# gcr_es17 register map
Registers are access not given, no defined reset value unless marked. A register's access mark holds for its fields unless they carry their own. Offsets are from the block's base; lines under a group give offsets from that group; [hi:lo] are bit positions; {n}, {i} and the like mark numbered series; 'fields as' and 'values as' point back to an identical list; <NAME> marks a mode.

## Memory map
0x40000000 GCR size 0x400 — Global Control Registers.

## GCR — Global Control Registers.
Base 0x40000000
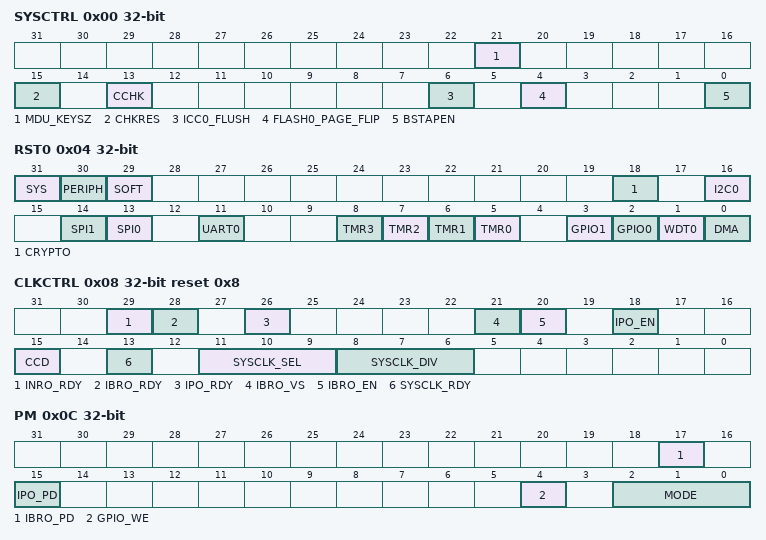
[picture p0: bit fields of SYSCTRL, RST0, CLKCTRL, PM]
0x00 SYSCTRL — System Control.
  [21] MDU_KEYSZ — MDU Key Size. This register defines the size of AES key that is used in the memory protection logic.
    0=128 bit key; 1=256 bit key
  [15] CHKRES — ROM Checksum Result. This bit is only valid when CHKRD=1.
    0=pass (ROM Checksum Correct.); 1=fail (ROM Checksum Fail.)
  [13] CCHK — Compute ROM Checksum. This bit is self-cleared when calculation is completed. Once set, software clearing this bit is ignored and the bit will remain set until the operation is completed.
    0=complete (No operation/complete.); 1=Start operation
  [6] ICC0_FLUSH — Code Cache Flush. This bit is used to flush the code caches and the instruction buffer of the Cortex-M4.
    0=Normal Code Cache Operation; 1=flush (Code Caches and CPU instruction buffer are flushed)
  [4] FLASH0_PAGE_FLIP — Flips the Flash bottom and top halves. (Depending on the total flash size, each half is either 256K or 512K). Initiating a flash page flip will cause a flush of both the data buffer on the DCODE bus and the internal instruction buffer.
    0=normal (Physical layout matches logical layout.); 1=swapped (Bottom half mapped to logical top half and vice versa.)
  [0] BSTAPEN — Boundary Scan TAP enable. When enabled, the JTAG port is connected to the Boundary Scan TAP. Otherwise, the port is connected to the ARM ICE function. This bit is reset by the POR. Reset value and access depend on the part number.
    0=dis (Boundary Scan TAP port disabled.); 1=en (Boundary Scan TAP port enabled.)
0x04 RST0 — Reset.
  [31] SYS — System Reset. Setting this bit to 1 resets the CPU core and all peripherals, including the watchdog timer.
  [30] PERIPH — Peripheral Reset. Setting this bit to 1 resets all peripherals. The CPU core, the watchdog timer, and all GPIO pins are unaffected by this reset.
  [29] SOFT — Soft Reset. Setting this bit to 1 resets everything except the CPU and the watchdog timer.
  [18] CRYPTO — Cryptographic Reset. Setting this bit to 1 resets the AES block, the SHA block and the DES block.
  [16] I2C0 — I2C0 Reset.
  [14] SPI1 — SPI1 Reset. Setting this bit to 1 resets all SPI 1 blocks.
  [13] SPI0 — SPI0 Reset. Setting this bit to 1 resets all SPI 0 blocks.
  [11] UART0 — UART0 Reset. Setting this bit to 1 resets all UART 0 blocks.
  [n+5] TMR{n} (n=0..3) — Timer{n} Reset. Setting this bit to 1 resets Timer {n} blocks.
  [3] GPIO1 — GPIO1 Reset. Setting this bit to 1 resets GPIO1 pins to their default states.
  [2] GPIO0 — GPIO0 Reset. Setting this bit to 1 resets GPIO0 pins to their default states.
  [1] WDT0 — Watchdog Timer Reset.
  [0] DMA — DMA Reset.
0x08 CLKCTRL reset 0x8 — Clock Control.
  [29] INRO_RDY — Internal Nano Ring Oscillator Low Frequency Reference Clock Ready.
  [28] IBRO_RDY — Internal Baud Rate Oscillator Ready.
  [26] IPO_RDY — Internal Primary Oscillator Ready.
  [21] IBRO_VS — 7.3728MHz Internal Oscillator Voltage Source Select
  [20] IBRO_EN — 8MHz High Frequency Internal Reference Clock Enable.
  [18] IPO_EN — 96MHz High Frequency Internal Reference Clock Enable.
  [15] CCD ro — Cryptographic clock divider
    0=non_div (The cryptographic accelerator clock is running in non-divided mode.); 1=div (The cryptographic accelerator clock is running in divided mode.)
  [13] SYSCLK_RDY ro — Clock Ready. This read only bit reflects whether the currently selected system clock source is running.
    0=busy (Switchover to the new clock source (as selected by CLKSEL) has not yet occurred.); 1=ready (System clock running from CLKSEL clock source.)
  [11:9] SYSCLK_SEL — Clock Source Select. This 3 bit field selects the source for the system clock.
    0=IPO (Internal Primary Oscilatior Clock); 3=INRO (8kHz Internal Nano Ring Oscillator is used for the system clock.); 5=IBRO (The internal Baud Rate oscillator is used for the system clock.)
  [8:6] SYSCLK_DIV — Prescaler Select. This 3 bit field sets the system operating frequency by controlling the prescaler that divides the output of the PLL0.
    0=div1 (Divide by 1.); 1=div2 (Divide by 2.); 2=div4 (Divide by 4.); 3=div8 (Divide by 8.); 4=div16 (Divide by 16.); 5=div32 (Divide by 32.); 6=div64 (Divide by 64.); 7=div128 (Divide by 128.)
0x0C PM — Power Management.
  [17] IBRO_PD — Internal Baud Rate Oscillator power down. This bit selects the power state in DEEPSLEEP mode.
    0=active (Mode is Active.); 1=deepsleep (Powered down in DEEPSLEEP.)
  [15] IPO_PD — Internal Primary Oscilator Power Down. This bit selects the power state in DEEPSLEEP mode.
    values as IBRO_PD
  [4] GPIO_WE — GPIO Wake Up Enable. This bit enables all GPIO pins as potential wakeup sources. Any GPIO configured for wakeup is capable of causing an exit from IDLE or STANDBY modes when this bit is set.
  [2:0] MODE — Operating Mode. This two bit field selects the current operating mode for the device. Note that code execution only occurs during ACTIVE mode.
    0=Active Mode; 2=DeepSleep Mode; 3=Shutdown Mode; 4=Backup Mode
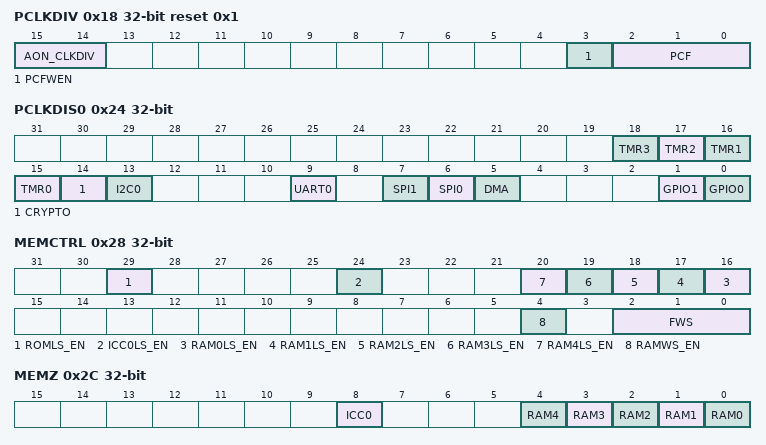
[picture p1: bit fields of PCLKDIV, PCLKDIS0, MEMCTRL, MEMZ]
0x18 PCLKDIV reset 0x1 — Peripheral Clock Divider.
  [15:14] AON_CLKDIV — Always-ON (AON) domain CLock Divider. These bits define the AON domain clock divider.
    0=div_4 (PCLK divide by 4.); 1=div_8 (PCLK divide by 8.); 2=div_16 (PCLK divide by 16.); 3=div_32 (PCLK divide by 32.)
  [3] PCFWEN — PCF Write Enable. This bit allows the PCF Register bits to be updated by Software.
    0=blocked (Writes to PCF are blocked.); 1=allowed (Writes to PCF are allowed)
  [2:0] PCF — These bits determine the clock frequency for the UART, I2C and Key Pad peripherals. These peripherals have an adaptive clock generator that dynamically adjusts the peripheral frequency based on the main system bus frequency. These bits are dynamically updated when the PLL0 is selected as the system clock source and are set by hardware. These bits determine the clock frequency for the UART, I2C and Key Pad peripherals. These peripherals have an adaptive clock generator that dynamically adjusts the peripheral frequency based on the main system bus frequency. These bits are dynamically updated when the PLL0 is selected as the system clock source and are set by hardware.
    2=96MHz; 3=48MHz; 4=24MHz; 5=12MHz; 6=6MHz; 7=3MHz
0x24 PCLKDIS0 — Peripheral Clock Disable.
  [all] fields
    0=en (enable it.); 1=dis (disable it.)
  [n+15] TMR{n} (n=0..3) — Timer {n} Disable.
  [14] CRYPTO — Crypto Disable.
  [13] I2C0 — I2C 0 Disable.
  [9] UART0 — UART 0 Disable.
  [7] SPI1 — SPI 1 Disable.
  [6] SPI0 — SPI 0 Disable.
  [5] DMA — DMA Disable.
  [1] GPIO1 — GPIO1 Disable.
  [0] GPIO0 — GPIO0 Clock Disable.
0x28 MEMCTRL — Memory Clock Control Register.
  [29] ROMLS_EN — ROM Light Sleep Mode.
    0=active (RAM is active.); 1=light_sleep (RAM is in Light Sleep mode.)
  [24] ICC0LS_EN — ICache RAM Light Sleep Mode.
    values as ROMLS_EN
  [n+16] RAM{n}LS_EN (n=0..4) — System RAM {n} Light Sleep Mode.
    values as ROMLS_EN
  [4] RAMWS_EN — SRAM Wait State Enable
  [2:0] FWS — Flash Wait State. These bits define the number of wait-state cycles per Flash data read access. Minimum wait state is 2.
0x2C MEMZ — Memory Zeroize Control.
  [all] fields
    0=nop (No operation/complete.); 1=Start operation
  [8] ICC0 — Instruction Cache.
  [n] RAM{n} (n=0..4) — System RAM Block {n}.
0x40 SYSST — System Status Register.
  [0] ICELOCK — ARM ICE Lock Status.
    0=unlocked (ICE is unlocked.); 1=locked (ICE is locked.)
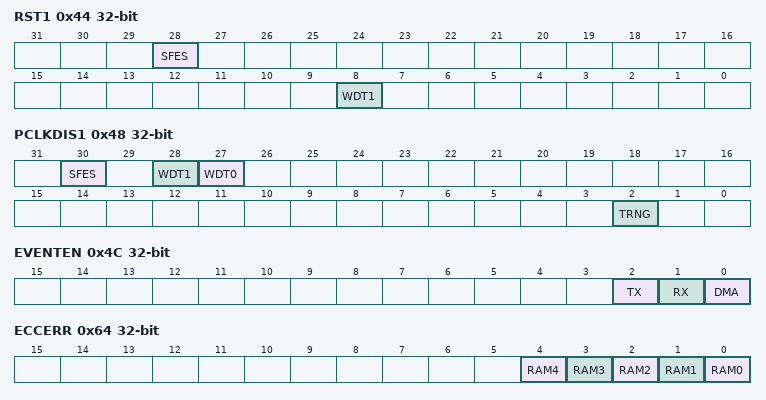
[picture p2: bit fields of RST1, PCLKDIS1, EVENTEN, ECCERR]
0x44 RST1 — Reset 1.
  [28] SFES — Serial Flash Emulation Slave Reset.
  [8] WDT1 — WDT1 Reset.
0x48 PCLKDIS1 — Peripheral Clock Disable.
  [30] SFES — Serial Flash emulation slave Clock Disable
  [28] WDT1 — WDT1 Clock Disable
  [27] WDT0 — WDT0 Clock Disable
  [2] TRNG — TRNG Disable.
0x4C EVENTEN — Event Enable Register.
  [2] TX — Enable TXEV pin event. When this bit is set, TXEV event from the CPU is output to GPIO[25].
  [1] RX — Enable RXEV pin event. When this bit is set, a logic high of GPIO0[24] will cause an RXEV event to wake the CPU from WFE sleep mode.
  [0] DMA — Enable DMA event. When this bit is set, a DMA event will cause an RXEV event to wake the CPU from WFE sleep mode.
0x50 REVISION ro
  [15:0] REVISION — Manufacturer Chip Revision.
0x54 SYSIE — System Status Interrupt Enable Register.
  [0] ICEUNLOCK — ARM ICE Unlock Interrupt Enable.
    0=dis (disabled.); 1=en (enabled.)
0x64 ECCERR — ECC Error Register
  [n] RAM{n} (n=0..4) — ECC System RAM{n} Error Flag. Write 1 to clear.
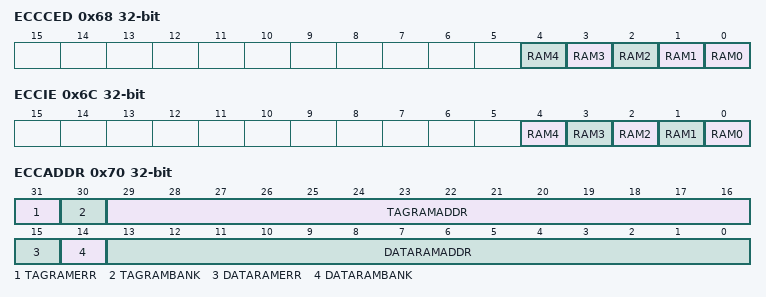
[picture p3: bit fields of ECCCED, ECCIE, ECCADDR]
0x68 ECCCED — ECC Not Double Error Detect Register
  [n] RAM{n} (n=1..4) — ECC System RAM{n} Not Double Error Detect. Write 1 to clear.
  [0] RAM0 — ECC System RAM0 Error Flag. Write 1 to clear.
0x6C ECCIE — ECC IRQ Enable Register
  [n] RAM{n} (n=0..4) — ECC System RAM{n} Interrupt Enable.
0x70 ECCADDR — ECC Error Address Register
  [31] TAGRAMERR — TAG RAM ERROR
  [30] TAGRAMBANK — ECC Error Address/TAG RAM Error Bank
  [29:16] TAGRAMADDR — ECC Error Address/TAG RAM Error Address
  [15] DATARAMERR — DATA RAM ERROR
  [14] DATARAMBANK — ECC Error Address/DATA RAM Error Bank
  [13:0] DATARAMADDR — ECC Error Address/DATA RAM Error Address
